AUTOSAR XML (schema 4-0-3)
# Copyright © Vector Informatik GmbH 2013
# License cannot be found!
# The created file must only be used with Vectors MICROSAR Basic Software. Please contact Vector Informatik to obtain a license.
standard types defined: boolean, float32, uint16, uint8
package /VehicleProject
  system System
package /NM
  nm config NmConfig: can-nm-cluster-coupling=coupled-cluster=CAN00
    can nm cluster CAN00: communication-cluster=PowerTrain, nm-channel-id=0
      can nm node Engine: controller=Engine/CT_CAN00, nm-if-ecu=Engine_CAN, tx-nm-pdu=NM_Engine
      can nm node Gateway: controller=Gateway/CT_CAN00, nm-if-ecu=Gateway_CAN, tx-nm-pdu=NM_Gateway_PowerTrain
    nm-if-ecus:
      nm ecu Engine_CAN: ecu-instance=Engine, nm-multiple-channels-enabled=false
      nm ecu Gateway_CAN: ecu-instance=Gateway, nm-multiple-channels-enabled=false
package /TP
  can tp config CAN00: communication-cluster=PowerTrain
    can tp channel TPCH: channel-id=0, channel-mode=FULL-DUPLEX-MODE
    tp-ecus:
      cycle-time-main-function=0.005, ecu-instance=Engine
      cycle-time-main-function=0.005, ecu-instance=Gateway
    can tp node TN_Engine: connector=Engine/CN_CAN00
    can tp node TN_Gateway: connector=Gateway/CN_CAN00
package /Cluster
  can cluster PowerTrain  # CAN communication matrix for body electronics ******************************************************* implemented: turn lights, warning lights, windows
    can cluster conditional New_Element_687: protocol-name=CAN
      can physical channel CHNL: comm-connectors=[Engine/CN_CAN00, Gateway/CN_CAN00]
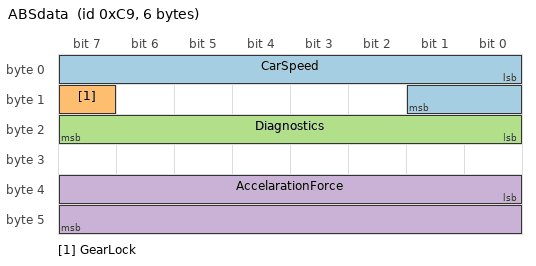
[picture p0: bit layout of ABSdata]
        frame ABSdata: id 0xC9, from Engine, frame-length=6, can-addressing-mode=STANDARD
          pdu ABSdata: length=6, minimum-delay=0.001, transmission-mode-false-timing=cyclic-timing={time-offset=0, time-period=0.05}, transmission-mode-true-timing=cyclic-timing={time-offset=0, time-period=0.05}, unused-bit-pattern=0
            signal CarSpeed: start 0, 10 bit, little-endian, init-value=0, base-type=uint16, compu {phys=raw*0.5; unit mph}, unit=mph, transfer-property=PENDING
            signal GearLock: start 15, 1 bit, little-endian, data-type-policy=OVERRIDE, init-value=0, base-type=boolean, compu {0=Gear_Lock_Off, 1=Gear_Lock_On}, transfer-property=PENDING
            signal Diagnostics: start 16, 8 bit, little-endian, init-value=0, base-type=uint8, transfer-property=PENDING
            signal AccelarationForce: start 32, 16 bit, little-endian, init-value=0, base-type=uint16, compu {phys=raw-10000; unit N}, unit=N, transfer-property=PENDING
        frame Diag_Request: id 0x200, frame-length=8, can-addressing-mode=STANDARD
          n pdu Diag_Request_Tp: length=8
        frame Diag_Response: id 0x400, frame-length=8, can-addressing-mode=STANDARD
          n pdu Diag_Response_Tp: length=8
        frame DiagRequest_Motor: id 0x601, from Gateway, frame-length=8, can-addressing-mode=STANDARD
          pdu DiagRequest_Motor: length=8, minimum-delay=0.001, unused-bit-pattern=0
        frame DiagResponse_Motor: id 0x608, from Engine, frame-length=8, can-addressing-mode=STANDARD
          pdu DiagResponse_Motor: length=8, minimum-delay=0.001, unused-bit-pattern=0
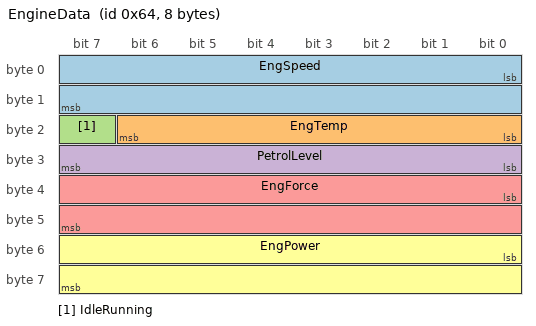
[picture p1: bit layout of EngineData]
        frame EngineData: id 0x64, from Engine, frame-length=8, can-addressing-mode=STANDARD
          pdu EngineData:
            length=8
            minimum-delay=0.001
            transmission-mode-condition{data-filter={data-filter-type=MASKED-NEW-DIFFERS-X, mask=4294967295, x=1}, i-signal-in-i-pdu=IdleRunning}
            transmission-mode-false-timing={cyclic-timing={time-offset=0, time-period=0.05}, event-controlled-timing={number-of-repetitions=0, repetition-period=0}}
            transmission-mode-true-timing=cyclic-timing={time-offset=0, time-period=0.1}
            unused-bit-pattern=0
            signal EngSpeed: start 0, 16 bit, little-endian, init-value=0, base-type=uint16, compu {; unit rpm}, unit=rpm, transfer-property=PENDING
            signal EngTemp: start 16, 7 bit, little-endian, init-value=0, base-type=uint8, compu {phys=raw*2-50; unit degC}, unit=degC, transfer-property=PENDING
            signal IdleRunning: start 23, 1 bit, little-endian, data-type-policy=OVERRIDE, init-value=0, base-type=boolean, compu {0=Running, 1=Idle}, transfer-property=PENDING
            signal PetrolLevel: start 24, 8 bit, little-endian, init-value=0, base-type=uint8, compu {; unit l}, unit=l, transfer-property=PENDING
            signal EngForce: start 32, 16 bit, little-endian, init-value=0, base-type=uint16, compu {; unit N}, unit=N, transfer-property=PENDING
            signal EngPower: start 48, 16 bit, little-endian, init-value=0, base-type=uint16, compu {phys=raw*0.01; unit kW}, unit=kW, transfer-property=PENDING
        frame EngineDataIEEE: id 0x66, from Engine, frame-length=8, can-addressing-mode=STANDARD
          pdu EngineDataIEEE: length=8, minimum-delay=0.001, transmission-mode-false-timing=cyclic-timing={time-offset=0, time-period=0.05}, transmission-mode-true-timing=cyclic-timing={time-offset=0, time-period=0.05}, unused-bit-pattern=0
            signal EngSpeedIEEE: start 0, 32 bit, little-endian, init-value=0, base-type=float32, compu {; unit rpm}, unit=rpm, transfer-property=PENDING
            signal EngForceIEEE: start 32, 32 bit, little-endian, init-value=0, base-type=float32, compu {; unit N}, unit=N, transfer-property=PENDING
        frame EngineStatus: id 0x65, from Engine, frame-length=1, can-addressing-mode=STANDARD
          pdu EngineStatus: length=1, minimum-delay=0.001, transmission-mode-false-timing=event-controlled-timing={number-of-repetitions=0, repetition-period=0}, transmission-mode-true-timing=event-controlled-timing={number-of-repetitions=0, repetition-period=0}, unused-bit-pattern=0
            transmission-mode-conditions:
              data-filter=data-filter-type=ALWAYS, i-signal-in-i-pdu=Status
              data-filter=data-filter-type=ALWAYS, i-signal-in-i-pdu=ErrorCode
            signal Status: start 0, 2 bit, little-endian, data-type-policy=OVERRIDE, init-value=0, base-type=uint8, compu {0=WakeUp, 1=Running, 2=GoSleep, 3=Error}, transfer-property=TRIGGERED-WITHOUT-REPETITION
            signal ErrorCode: start 2, 6 bit, little-endian, init-value=0, base-type=uint8, transfer-property=TRIGGERED-WITHOUT-REPETITION
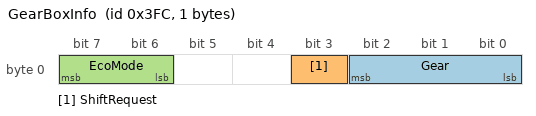
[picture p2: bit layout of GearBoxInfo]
        frame GearBoxInfo: id 0x3FC, from Engine, to Gateway, frame-length=1, can-addressing-mode=STANDARD
          pdu GearBoxInfo: length=1, minimum-delay=0.001, transmission-mode-false-timing=cyclic-timing={time-offset=0, time-period=0.05}, transmission-mode-true-timing=cyclic-timing={time-offset=0, time-period=0.05}, unused-bit-pattern=0
            signal Gear: start 0, 3 bit, little-endian, data-type-policy=OVERRIDE, init-value=0, base-type=uint8, compu {0=Idle, 1..5=Gear_1..Gear_5}, transfer-property=PENDING, to Gateway
            signal ShiftRequest: start 3, 1 bit, little-endian, data-type-policy=OVERRIDE, init-value=0, base-type=boolean, compu {0=Shift_Request_Off, 1=Shift_Request_On}, transfer-property=PENDING
            signal EcoMode: start 6, 2 bit, little-endian, init-value=0, base-type=uint8, transfer-property=PENDING
        frame Ignition_Info: id 0x67, from Gateway, to Engine, frame-length=2, can-addressing-mode=STANDARD
          pdu Ignition_Info: length=2, minimum-delay=0.001, transmission-mode-false-timing=cyclic-timing={time-offset=0, time-period=0.02}, transmission-mode-true-timing=cyclic-timing={time-offset=0, time-period=0.02}, unused-bit-pattern=0
            signal StarterKey: start 0, 1 bit, little-endian, init-value=0, base-type=boolean, transfer-property=PENDING, to Engine
        frame NM_Engine: id 0x51B, from Engine, frame-length=4, can-addressing-mode=STANDARD
          nm pdu NM_Engine: length=4, unused-bit-pattern=0
            signal NodeIdentifier_Engine: start 0, 8 bit, little-endian, data-type-policy=OVERRIDE
        frame NM_Gateway_PowerTrain: id 0x51A, from Gateway, frame-length=4, can-addressing-mode=STANDARD
          nm pdu NM_Gateway_PowerTrain: length=4, unused-bit-pattern=0
            signal NodeIdentifier_Gw: start 0, 8 bit, little-endian, data-type-policy=OVERRIDE
        pdu triggering PT_Diag_Request: pdu=Diag_Request
        pdu triggering PT_Diag_Response: pdu=Diag_Response
package /ECU
  ecu instance Engine: associated-com-i-pdu-group=[Engine_oCAN00_Rx, Engine_oCAN00_Tx], com-configuration-rx-time-base=0.001, com-configuration-tx-time-base=0.001
    can communication controller CT_CAN00
    can communication connector CN_CAN00: comm-controller=Engine/CT_CAN00
  ecu instance Gateway: associated-com-i-pdu-group=[Gateway_oCAN00_Rx, Gateway_oCAN00_Tx], com-configuration-rx-time-base=0.001, com-configuration-tx-time-base=0.001
    can communication controller CT_CAN00
    can communication connector CN_CAN00: comm-controller=Gateway/CT_CAN00
package /IPDUGroup
  4 x i signal i pdu group:
    Engine_oCAN00_Rx: communication-direction=IN, i-signal-i-pdus=Ignition_Info
    Engine_oCAN00_Tx: communication-direction=OUT, i-signal-i-pdus=[ABSdata, DiagResponse_Motor, EngineData, EngineDataIEEE, EngineStatus, GearBoxInfo]
    Gateway_oCAN00_Rx: communication-direction=IN, i-signal-i-pdus=GearBoxInfo
    Gateway_oCAN00_Tx: communication-direction=OUT, i-signal-i-pdus=[DiagRequest_Motor, Ignition_Info]
package /PDU
  dcm i pdu Diag_Request: length=8, diag-pdu-type=DIAG-REQUEST
  dcm i pdu Diag_Response: length=8, diag-pdu-type=DIAG-RESPONSE
package /DataType/Unit
  6 x unit:
    U_degC: display-name=degC
    U_kW: display-name=kW
    U_l: display-name=l
    U_mph: display-name=mph
    U_N: display-name=N
    U_rpm: display-name=rpm
